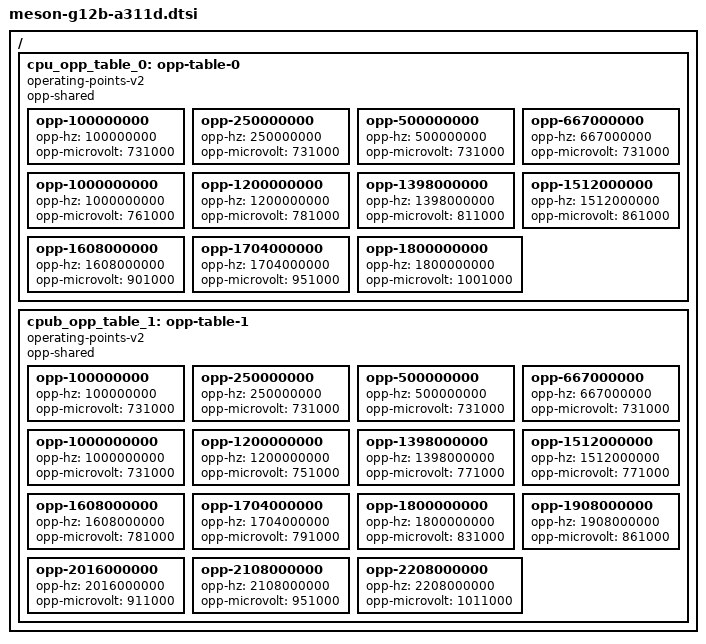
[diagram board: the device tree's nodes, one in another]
// SPDX-License-Identifier: (GPL-2.0+ OR MIT)
/*
 * Copyright (c) 2019 BayLibre, SAS
 * Author: Neil Armstrong <narmstrong@baylibre.com>
 */

#include "meson-g12b.dtsi"

/ {
	cpu_opp_table_0: opp-table-0 {
		compatible = "operating-points-v2";
		opp-shared;

		opp-100000000 {
			opp-hz = /bits/ 64 <100000000>;
			opp-microvolt = <731000>;
		};

		opp-250000000 {
			opp-hz = /bits/ 64 <250000000>;
			opp-microvolt = <731000>;
		};

		opp-500000000 {
			opp-hz = /bits/ 64 <500000000>;
			opp-microvolt = <731000>;
		};

		opp-667000000 {
			opp-hz = /bits/ 64 <667000000>;
			opp-microvolt = <731000>;
		};

		opp-1000000000 {
			opp-hz = /bits/ 64 <1000000000>;
			opp-microvolt = <761000>;
		};

		opp-1200000000 {
			opp-hz = /bits/ 64 <1200000000>;
			opp-microvolt = <781000>;
		};

		opp-1398000000 {
			opp-hz = /bits/ 64 <1398000000>;
			opp-microvolt = <811000>;
		};

		opp-1512000000 {
			opp-hz = /bits/ 64 <1512000000>;
			opp-microvolt = <861000>;
		};

		opp-1608000000 {
			opp-hz = /bits/ 64 <1608000000>;
			opp-microvolt = <901000>;
		};

		opp-1704000000 {
			opp-hz = /bits/ 64 <1704000000>;
			opp-microvolt = <951000>;
		};

		opp-1800000000 {
			opp-hz = /bits/ 64 <1800000000>;
			opp-microvolt = <1001000>;
		};
	};

	cpub_opp_table_1: opp-table-1 {
		compatible = "operating-points-v2";
		opp-shared;

		opp-100000000 {
			opp-hz = /bits/ 64 <100000000>;
			opp-microvolt = <731000>;
		};

		opp-250000000 {
			opp-hz = /bits/ 64 <250000000>;
			opp-microvolt = <731000>;
		};

		opp-500000000 {
			opp-hz = /bits/ 64 <500000000>;
			opp-microvolt = <731000>;
		};

		opp-667000000 {
			opp-hz = /bits/ 64 <667000000>;
			opp-microvolt = <731000>;
		};

		opp-1000000000 {
			opp-hz = /bits/ 64 <1000000000>;
			opp-microvolt = <731000>;
		};

		opp-1200000000 {
			opp-hz = /bits/ 64 <1200000000>;
			opp-microvolt = <751000>;
		};

		opp-1398000000 {
			opp-hz = /bits/ 64 <1398000000>;
			opp-microvolt = <771000>;
		};

		opp-1512000000 {
			opp-hz = /bits/ 64 <1512000000>;
			opp-microvolt = <771000>;
		};

		opp-1608000000 {
			opp-hz = /bits/ 64 <1608000000>;
			opp-microvolt = <781000>;
		};

		opp-1704000000 {
			opp-hz = /bits/ 64 <1704000000>;
			opp-microvolt = <791000>;
		};

		opp-1800000000 {
			opp-hz = /bits/ 64 <1800000000>;
			opp-microvolt = <831000>;
		};

                opp-1908000000 {
                        opp-hz = /bits/ 64 <1908000000>;
                        opp-microvolt = <861000>;
                };

                opp-2016000000 {
                        opp-hz = /bits/ 64 <2016000000>;
                        opp-microvolt = <911000>;
                };

                opp-2108000000 {
                        opp-hz = /bits/ 64 <2108000000>;
                        opp-microvolt = <951000>;
                };

                opp-2208000000 {
                        opp-hz = /bits/ 64 <2208000000>;
                        opp-microvolt = <1011000>;
                };
	};
};
